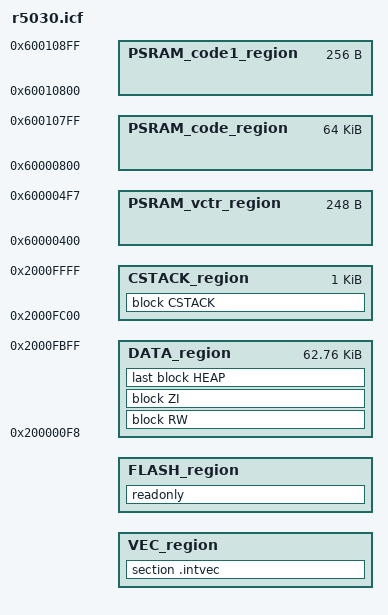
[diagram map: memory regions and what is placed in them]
/* Sizes and locations */

define symbol __start_flash__       = 0x00000000        //for PSRAM 0x60000000;
define symbol __size_flash__        = 0x10000;			//64K
define symbol __start_ram__         = 0x20000000;       // For PSRAM 0x60000400; data part not verified
define symbol __size_ram__          = 0x10000;
define symbol __size_flash_vtable__ = 0xF8;
define symbol __size_ram_vtable__   = 0xF8;  /* (F8=184)Reserve space for dynamic vectors mapped to RAM (see cmsis_nvic.c) */

/*  PSRAM symbols   */
define symbol __start_psram__       = 0x60000400;
define symbol __psram_data_size__   = 0x00;              //0x100;
define symbol __psram_code_size__   = 0x10000;
define symbol __psram_offset__      = 0x400;             //0x1000;

if (isdefinedsymbol(__stack_size__)) {
  define symbol __size_cstack__        = __stack_size__;
} else {
  define symbol __size_cstack__        = 1024;
}

if (isdefinedsymbol(__heap_size__)) {
  define symbol __size_heap__          = __heap_size__;
} else {
  define symbol __size_heap__          = (512);
}

/* Memory regions */

define symbol __region_INTVEC_FLASH_start__ = __start_flash__;
define symbol __region_INTVEC_FLASH_end__   = __start_flash__ + __size_flash_vtable__ - 1;
define symbol __region_TEXT_start__         = __start_flash__ + __size_flash_vtable__; /* Leave room for flash vector table at start */
define symbol __region_TEXT_end__           = __start_flash__ + __size_flash__ - 1;
define symbol __region_INTVEC_RAM_start__   = __start_ram__;
define symbol __region_DATA_start__         = __start_ram__ + __size_ram_vtable__; /* Leave room for RAM vector table at start */
define symbol __region_DATA_end__           = __start_ram__ + __size_ram__ - __size_cstack__ - 1; /* Leave room for stack at end */
define symbol __region_CSTACK_start__       = __start_ram__ + __size_ram__ - __size_cstack__;
define symbol __region_CSTACK_end__         = __start_ram__ + __size_ram__ - 1;

/*  PSRAM symbols    */
define symbol __psram_vector_start__        = __start_psram__;
define symbol __region_vector_psram_end__   = __start_psram__ + __size_flash_vtable__ - 1;
define symbol __psram_data_start__          = __start_psram__+__psram_offset__;
define symbol __region_data_psram_end__     = __start_psram__ + __psram_offset__ +__psram_data_size__ - 1;
define symbol __psram_code_start__          = __start_psram__ + __psram_offset__ +__psram_data_size__;
define symbol __region_code_psram_end__     = __start_psram__ + __psram_offset__ +__psram_data_size__ +__psram_code_size__ - 1;
define symbol __psram_code1_start__          = __start_psram__ + __psram_offset__ +__psram_data_size__ +__psram_code_size__ ;
define symbol __region_code1_psram_end__     = __start_psram__ + __psram_offset__ +__psram_data_size__ +__psram_code_size__ + 0x100 - 1;

define memory mem with size = 4G;
define region VEC_region     = mem:[from __region_INTVEC_FLASH_start__ to __region_INTVEC_FLASH_end__];
define region FLASH_region   = mem:[from __region_TEXT_start__ to __region_TEXT_end__];
define region DATA_region    = mem:[from __region_DATA_start__ to __region_DATA_end__];
define region CSTACK_region  = mem:[from __region_CSTACK_start__ to __region_CSTACK_end__];

/*  PSRAM sections   */
define region PSRAM_vctr_region   = mem:[from __psram_vector_start__ to __region_vector_psram_end__];
define region PSRAM_data_region   = mem:[from __psram_data_start__ to __region_data_psram_end__];
define region PSRAM_code_region   = mem:[from __psram_code_start__ to __region_code_psram_end__];
define region PSRAM_code1_region   = mem:[from __psram_code1_start__ to __region_code1_psram_end__];

define block CSTACK     with alignment = 8, size = __size_cstack__     { };
define block HEAP       with alignment = 8, size = __size_heap__       { };
define block RW         { readwrite };
//define block RO_DATA    { ro data  };
//define block RO_CODE    { ro code  };
define block ZI         { zi };

/* Place sections */

initialize by copy { readwrite, zi };
//initialize by copy { readonly};
initialize by copy { section .intvec };
do not initialize  { section .noinit };

//place at address mem:__region_INTVEC_FLASH_start__  { section .intvec }; /* */
place in VEC_region    { section .intvec }; 
place in FLASH_region    { readonly};
place in DATA_region   { block RW };
place in DATA_region   { block ZI };
place in DATA_region   { last block HEAP };
place in CSTACK_region { block CSTACK };s


//place in PSRAM_code1_region  { readonly section .text };
//place in PSRAM_data_region  { readwrite section MY_DATA };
